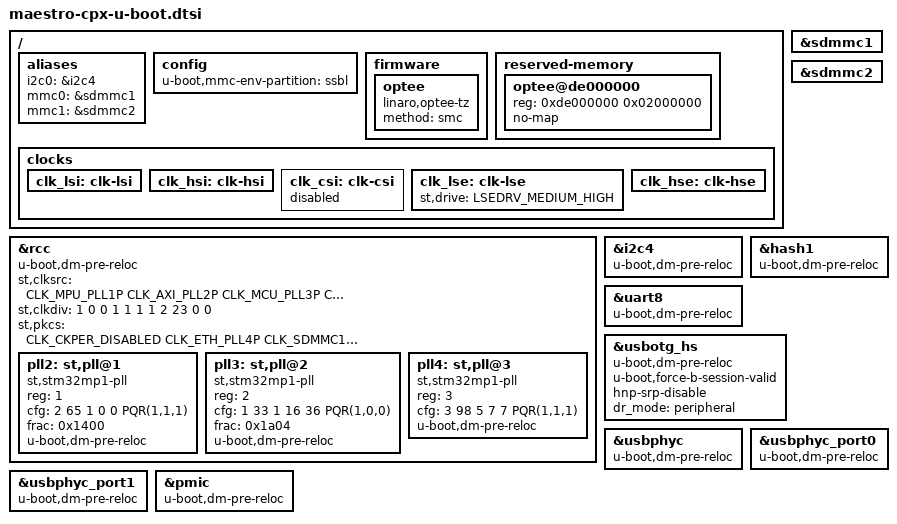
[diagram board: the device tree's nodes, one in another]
/* SPDX-License-Identifier: GPL-2.0+ OR BSD-3-Clause*/
/*
 * Copyright (C) 2021, STMicroelectronics - All Rights Reserved
 * Author: STM32CubeMX code generation for STMicroelectronics.
 */

/* For more information on Device Tree configuration, please refer to
 * https://wiki.st.com/stm32mpu/wiki/Category:Device_tree_configuration
 */

#include <dt-bindings/clock/stm32mp1-clksrc.h>
#include "maestro-cpx.dtsi"

#include "stm32mp15-u-boot.dtsi"
#include "stm32mp15-ddr.dtsi"

/* USER CODE BEGIN includes */
/* USER CODE END includes */

/ {

	/* USER CODE BEGIN root */
	aliases {
		i2c0 = &i2c4;
		mmc0 = &sdmmc1;
		mmc1 = &sdmmc2;
	};

	config {
		u-boot,mmc-env-partition = "ssbl";
	};

	firmware {
		optee {
			compatible = "linaro,optee-tz";
			method = "smc";
		};
	};

	reserved-memory {
		optee@de000000 {
			reg = <0xde000000 0x02000000>;
			no-map;
		};
	};
	/* USER CODE END root */

	clocks {
		/* USER CODE BEGIN clocks */
		/* USER CODE END clocks */

#ifndef CONFIG_STM32MP1_TRUSTED
		clk_lsi: clk-lsi {

			/* USER CODE BEGIN clk_lsi */
			/* USER CODE END clk_lsi */
		};
		clk_hsi: clk-hsi {

			/* USER CODE BEGIN clk_hsi */
			/* USER CODE END clk_hsi */
		};
		clk_csi: clk-csi {
			status = "disabled";

			/* USER CODE BEGIN clk_csi */
			/* USER CODE END clk_csi */
		};
		clk_lse: clk-lse {
			st,drive = < LSEDRV_MEDIUM_HIGH >;

			/* USER CODE BEGIN clk_lse */
			/* USER CODE END clk_lse */
		};
		clk_hse: clk-hse {

			/* USER CODE BEGIN clk_hse */
			/* USER CODE END clk_hse */
		};
#endif	/*CONFIG_STM32MP1_TRUSTED*/
	};

}; /*root*/

#ifndef CONFIG_STM32MP1_TRUSTED

&rcc {
	u-boot,dm-pre-reloc;
	st,clksrc = <
		CLK_MPU_PLL1P
		CLK_AXI_PLL2P
		CLK_MCU_PLL3P
		CLK_PLL12_HSE
		CLK_PLL3_HSE
		CLK_PLL4_HSE
		CLK_RTC_LSE
		CLK_MCO1_DISABLED
		CLK_MCO2_DISABLED
	>;
	st,clkdiv = <
		1 		/*MPU*/
		0 		/*AXI*/
		0 		/*MCU*/
		1 		/*APB1*/
		1 		/*APB2*/
		1 		/*APB3*/
		1 		/*APB4*/
		2 		/*APB5*/
		23 		/*RTC*/
		0 		/*MCO1*/
		0 		/*MCO2*/
	>;
	st,pkcs = <
		CLK_CKPER_DISABLED
		CLK_ETH_PLL4P
		CLK_SDMMC12_PLL4P
		CLK_DSI_DSIPLL
		CLK_STGEN_HSE
		CLK_USBPHY_HSE
		CLK_SPI2S1_DISABLED
		CLK_SPI2S23_DISABLED
		CLK_SPI45_PCLK2
		CLK_SPI6_DISABLED
		CLK_I2C46_HSI
		CLK_SDMMC3_DISABLED
		CLK_USBO_USBPHY
		CLK_ADC_DISABLED
		CLK_CEC_DISABLED
		CLK_I2C12_HSI
		CLK_I2C35_PCLK1
		CLK_UART1_DISABLED
		CLK_UART24_HSI
		CLK_UART35_HSI
		CLK_UART6_DISABLED
		CLK_UART78_HSI
		CLK_SPDIF_DISABLED
		CLK_FDCAN_PLL4R
		CLK_SAI1_DISABLED
		CLK_SAI2_DISABLED
		CLK_SAI3_DISABLED
		CLK_SAI4_DISABLED
		CLK_RNG1_LSI
		CLK_RNG2_LSI
		CLK_LPTIM1_DISABLED
		CLK_LPTIM23_DISABLED
		CLK_LPTIM45_DISABLED
	>;
	pll2:st,pll@1 {
		compatible = "st,stm32mp1-pll";
		reg = <1>;
		cfg = < 2 65 1 0 0 PQR(1,1,1) >;
		frac = < 0x1400 >;
		u-boot,dm-pre-reloc;
	};
	pll3:st,pll@2 {
		compatible = "st,stm32mp1-pll";
		reg = <2>;
		cfg = < 1 33 1 16 36 PQR(1,0,0) >;
		frac = < 0x1a04 >;
		u-boot,dm-pre-reloc;
	};
	pll4:st,pll@3 {
		compatible = "st,stm32mp1-pll";
		reg = <3>;
		cfg = < 3 98 5 7 7 PQR(1,1,1) >;
		u-boot,dm-pre-reloc;
	};
};

&i2c4{
	u-boot,dm-pre-reloc;

	/* USER CODE BEGIN i2c4 */
	/* USER CODE END i2c4 */
};

&sdmmc1{
	u-boot,dm-spl;

	/* USER CODE BEGIN sdmmc1 */
	/* USER CODE END sdmmc1 */
};

&sdmmc2{
	u-boot,dm-spl;

	/* USER CODE BEGIN sdmmc2 */
	/* USER CODE END sdmmc2 */
};

#endif	/*CONFIG_STM32MP1_TRUSTED*/

&hash1{
	u-boot,dm-pre-reloc;

	/* USER CODE BEGIN hash1 */
	/* USER CODE END hash1 */
};

&uart8{
	u-boot,dm-pre-reloc;

	/* USER CODE BEGIN uart8 */
	/* USER CODE END uart8 */
};

&usbotg_hs{
	u-boot,dm-pre-reloc;

	/* USER CODE BEGIN usbotg_hs */
	u-boot,force-b-session-valid;
	hnp-srp-disable;
	dr_mode = "peripheral";      
	/* USER CODE END usbotg_hs */
};

&usbphyc{
	u-boot,dm-pre-reloc;

	/* USER CODE BEGIN usbphyc */
	/* USER CODE END usbphyc */
};

&usbphyc_port0{
	u-boot,dm-pre-reloc;

	/* USER CODE BEGIN usbphyc_port0 */
	/* USER CODE END usbphyc_port0 */
};

&usbphyc_port1{
	u-boot,dm-pre-reloc;

	/* USER CODE BEGIN usbphyc_port1 */
	/* USER CODE END usbphyc_port1 */
};

/* USER CODE BEGIN addons */
&pmic {
	u-boot,dm-pre-reloc;
};
/* USER CODE END addons */

